VERSION ""

NS_ :

BS_:

BU_: DisplayVCAN

BO_ 71 MCR_request: 6 Vector__XXX
 SG_ MCR_request : 0|1@1+ (1,0) [0|1] "" Vector__XXX

BO_ 48 Pump_Override: 2 Vector__XXX
 SG_ PTE_Override : 8|1@1+ (1,0) [0|1] "" Vector__XXX
 SG_ CAC_Override : 0|1@1+ (1,0) [0|1] "" Vector__XXX

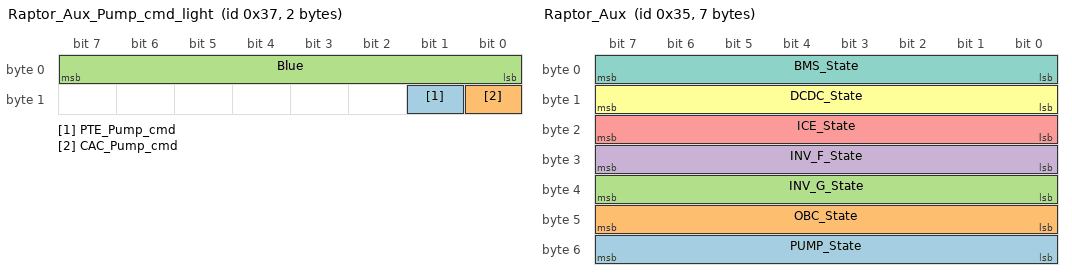
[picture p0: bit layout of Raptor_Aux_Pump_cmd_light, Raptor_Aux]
BO_ 55 Raptor_Aux_Pump_cmd_light: 2 Vector__XXX
 SG_ PTE_Pump_cmd : 9|1@1+ (1,0) [0|1] "" Vector__XXX
 SG_ CAC_Pump_cmd : 8|1@1+ (1,0) [0|1] "" Vector__XXX
 SG_ Blue : 0|8@1+ (1,0) [0|255] "" Vector__XXX

BO_ 53 Raptor_Aux: 7 Vector__XXX
 SG_ PUMP_State : 48|8@1+ (1,0) [0|0] "" Vector__XXX
 SG_ OBC_State : 40|8@1+ (1,0) [0|0] "" Vector__XXX
 SG_ INV_G_State : 32|8@1+ (1,0) [0|0] "" Vector__XXX
 SG_ INV_F_State : 24|8@1+ (1,0) [0|0] "" Vector__XXX
 SG_ ICE_State : 16|8@1+ (1,0) [0|0] "" Vector__XXX
 SG_ DCDC_State : 8|8@1+ (1,0) [0|0] "" Vector__XXX
 SG_ BMS_State : 0|8@1+ (1,0) [0|0] "" Vector__XXX

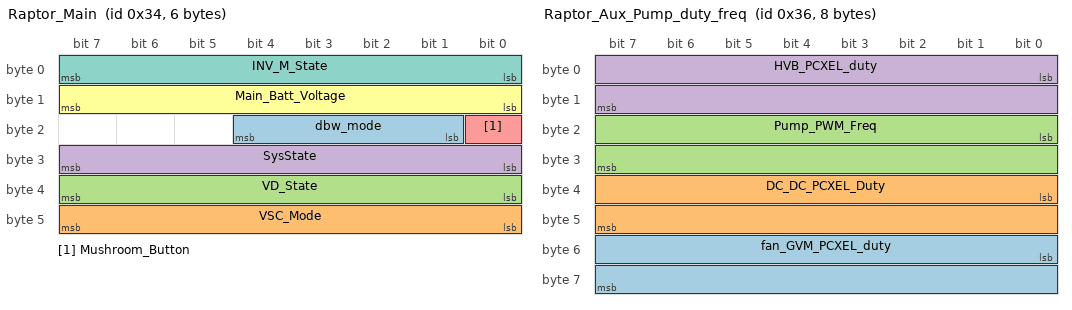
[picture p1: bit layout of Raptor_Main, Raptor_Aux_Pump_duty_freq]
BO_ 52 Raptor_Main: 6 Vector__XXX
 SG_ dbw_mode : 17|4@1+ (1,0) [0|15] "" Vector__XXX
 SG_ VSC_Mode : 40|8@1+ (1,0) [0|255] "" Vector__XXX
 SG_ VD_State : 32|8@1+ (1,0) [0|0] "" Vector__XXX
 SG_ SysState : 24|8@1+ (1,0) [0|0] "" Vector__XXX
 SG_ Mushroom_Button : 16|1@1+ (1,0) [0|1] "" Vector__XXX
 SG_ Main_Batt_Voltage : 8|8@1+ (0.1,0) [0|255] "V" Vector__XXX
 SG_ INV_M_State : 0|8@1+ (1,0) [0|0] "" Vector__XXX

BO_ 54 Raptor_Aux_Pump_duty_freq: 8 Vector__XXX
 SG_ fan_GVM_PCXEL_duty : 48|16@1+ (1,0) [0|65535] "" Vector__XXX
 SG_ DC_DC_PCXEL_Duty : 32|16@1+ (1,0) [0|65535] "" Vector__XXX
 SG_ Pump_PWM_Freq : 16|16@1+ (1,0) [0|65535] "Hz" Vector__XXX
 SG_ HVB_PCXEL_duty : 0|16@1+ (1,0) [0|65535] "" Vector__XXX

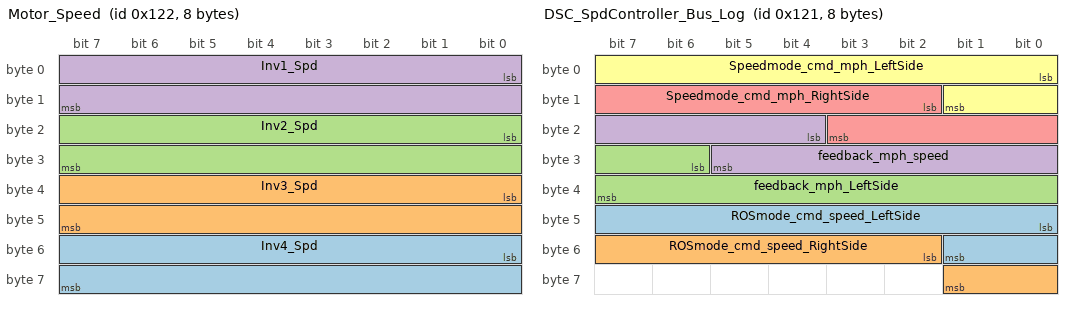
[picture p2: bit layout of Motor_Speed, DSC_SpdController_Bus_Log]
BO_ 290 Motor_Speed: 8 Vector__XXX
 SG_ Inv4_Spd : 48|16@1- (1,0) [-32768|32767] "rpm" Vector__XXX
 SG_ Inv3_Spd : 32|16@1- (1,0) [-32768|32767] "rpm" Vector__XXX
 SG_ Inv2_Spd : 16|16@1- (1,0) [-32768|32767] "rpm" Vector__XXX
 SG_ Inv1_Spd : 0|16@1- (1,0) [-32768|32767] "rpm" Vector__XXX

BO_ 289 DSC_SpdController_Bus_Log: 8 Vector__XXX
 SG_ ROSmode_cmd_speed_LeftSide : 40|10@1+ (0.1,0) [0|1023] "" Vector__XXX
 SG_ ROSmode_cmd_speed_RightSide : 50|8@1+ (0.1,0) [0|255] "" Vector__XXX
 SG_ feedback_mph_LeftSide : 30|10@1- (0.1,0) [-513|511] "mph" Vector__XXX
 SG_ feedback_mph_speed : 20|10@1- (0.1,0) [-513|511] "mph" Vector__XXX
 SG_ Speedmode_cmd_mph_RightSide : 10|10@1- (0.1,0) [-513|511] "mph" Vector__XXX
 SG_ Speedmode_cmd_mph_LeftSide : 0|10@1- (0.1,0) [-513|511] "mph" Vector__XXX

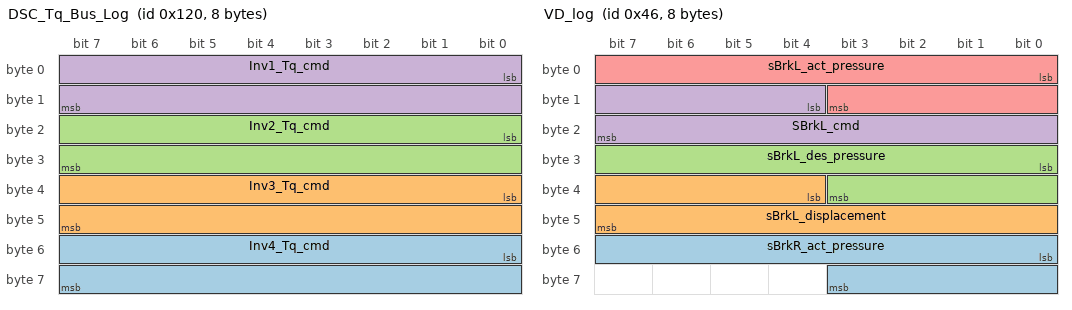
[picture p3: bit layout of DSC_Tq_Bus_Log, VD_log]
BO_ 288 DSC_Tq_Bus_Log: 8 Vector__XXX
 SG_ Inv4_Tq_cmd : 48|16@1- (1,0) [-3276.8|3276.7] "Nm" Vector__XXX
 SG_ Inv3_Tq_cmd : 32|16@1- (1,0) [-3276.8|3276.7] "Nm" Vector__XXX
 SG_ Inv2_Tq_cmd : 16|16@1- (1,0) [-3276.8|3276.7] "Nm" Vector__XXX
 SG_ Inv1_Tq_cmd : 0|16@1- (0.1,0) [-3276.8|3276.7] "Nm" Vector__XXX

BO_ 70 VD_log: 8 Vector__XXX
 SG_ sBrkR_act_pressure : 48|12@1+ (1,0) [0|4095] "" Vector__XXX
 SG_ sBrkL_displacement : 36|12@1+ (1,0) [0|4095] "" Vector__XXX
 SG_ sBrkL_des_pressure : 24|12@1- (0.05,0) [-1|90] "" Vector__XXX
 SG_ SBrkL_cmd : 12|12@1- (0.1,0) [-100|100] "" Vector__XXX
 SG_ sBrkL_act_pressure : 0|12@1+ (1,0) [0|4095] "" Vector__XXX

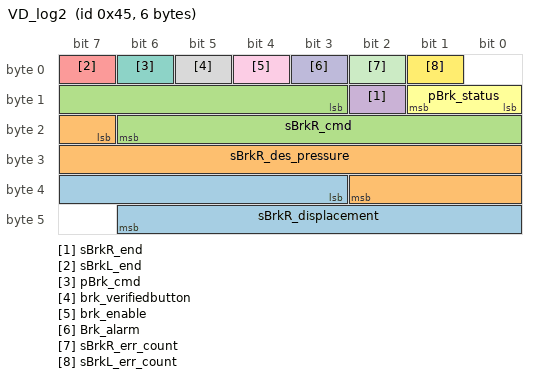
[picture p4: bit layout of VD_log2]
BO_ 69 VD_log2: 6 Vector__XXX
 SG_ sBrkR_displacement : 35|12@1+ (1,0) [0|4095] "" Vector__XXX
 SG_ sBrkR_des_pressure : 23|12@1- (0.05,0) [-1|90] "" Vector__XXX
 SG_ sBrkR_cmd : 11|12@1- (0.1,0) [-100|100] "" Vector__XXX
 SG_ sBrkR_end : 10|1@1+ (1,0) [0|1] "" Vector__XXX
 SG_ sBrkL_end : 7|1@1+ (1,0) [0|1] "" Vector__XXX
 SG_ pBrk_status : 8|2@1+ (1,0) [0|3] "" Vector__XXX
 SG_ pBrk_cmd : 6|1@1+ (1,0) [0|1] "" Vector__XXX
 SG_ brk_verifiedbutton : 5|1@1+ (1,0) [0|1] "" Vector__XXX
 SG_ brk_enable : 4|1@1+ (1,0) [0|1] "" Vector__XXX
 SG_ Brk_alarm : 3|1@1+ (1,0) [0|1] "" Vector__XXX
 SG_ sBrkR_err_count : 2|1@1+ (1,0) [0|1] "" Vector__XXX
 SG_ sBrkL_err_count : 1|1@1+ (1,0) [0|1] "" Vector__XXX

CM_ SG_ 52 Main_Batt_Voltage "Put a gain of 10 at the input battery voltage";
BA_DEF_  "BusType" STRING ;
BA_DEF_DEF_  "BusType" "CAN";
